# d_ip_ana_test_annex_syn: IP-XACT component
VLNV origen-sdk.org:id:d_ip_ana_test_annex_syn:

## Address spaces and blocks
RegisterMap.: base 0x40000000, range 8, width 32

## Registers
Registers are 16-bit, read-write, reset 0x8000 unless marked. A register's access mark holds for its fields unless they carry their own. Offsets are from the block's base; lines under a group give offsets from that group; [hi:lo] are bit positions; {n}, {i} and the like mark numbered series; 'fields as' and 'values as' point back to an identical list; <NAME> marks a mode.

## RegisterMap.block0
Base 0x40000000
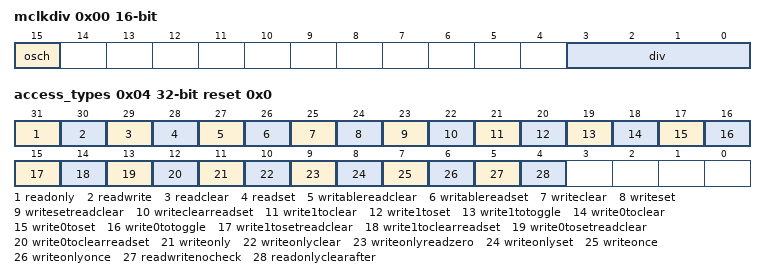
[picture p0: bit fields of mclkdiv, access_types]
0x00 mclkdiv — MPU Clock Divider Register
  [15] osch — Oscillator (Hi)
    0=Clock is the externally supplied bus clock bus_clk; 1=Clock is the internal oscillator from the hardblock
  [3:0] div — Divider Value
0x04 access_types 32-bit reset 0x0 — Access Type Test Register
  [31] readonly ro, [30] readwrite, [29] readclear ro read-clears, [28] readset ro read-sets, [27] writablereadclear read-clears, [26] writablereadset read-sets, [25] writeclear write-clears, [24] writeset write-sets, [23] writesetreadclear write-sets read-clears, [22] writeclearreadset write-clears read-sets, [21] write1toclear write-1-clears, [20] write1toset write-1-sets, [19] write1totoggle write-1-toggles, [18] write0toclear write-0-clears, [17] write0toset write-0-sets, [16] write0totoggle write-0-toggles, [15] write1tosetreadclear write-1-sets read-clears, [14] write1toclearreadset write-1-clears read-sets, [13] write0tosetreadclear write-0-sets read-clears, [12] write0toclearreadset write-0-clears read-sets, [11] writeonly wo, [10] writeonlyclear wo write-clears, [9] writeonlyreadzero wo, [8] writeonlyset wo write-sets, [7] writeonce rw-once, [6] writeonlyonce write-once, [5] readwritenocheck, [4] readonlyclearafter ro read-clears
